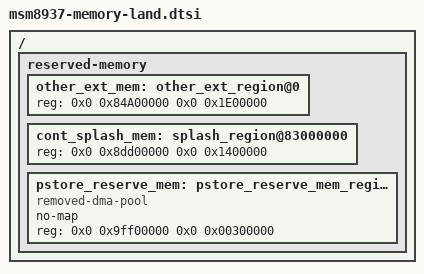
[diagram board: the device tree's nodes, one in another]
/ {
	reserved-memory {
		other_ext_mem: other_ext_region@0 {
			reg = <0x0 0x84A00000 0x0 0x1E00000>;
		};

		cont_splash_mem: splash_region@83000000 {
			reg = <0x0 0x8dd00000 0x0 0x1400000>;
		};

		pstore_reserve_mem: pstore_reserve_mem_region@0 {
			compatible = "removed-dma-pool";
			no-map;
			reg = <0x0 0x9ff00000 0x0 0x00300000>;
		};
	};
};
